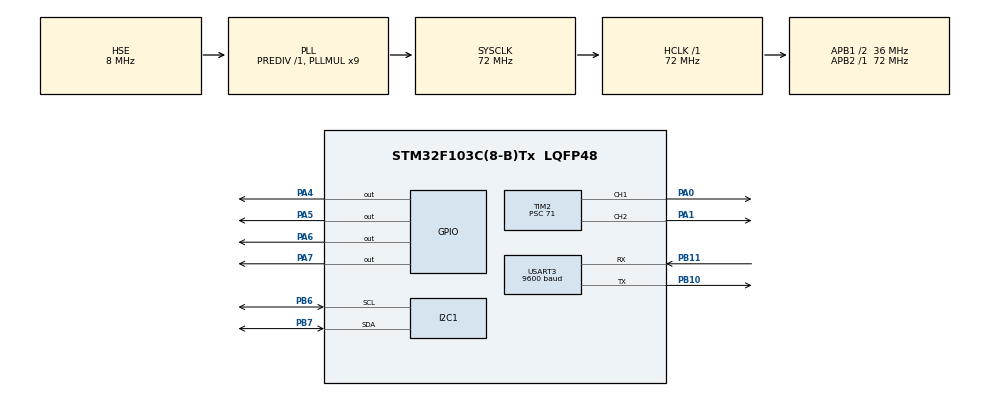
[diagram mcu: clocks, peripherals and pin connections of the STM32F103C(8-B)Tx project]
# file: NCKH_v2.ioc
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Mcu.Family=STM32F1
Mcu.Name=STM32F103C(8-B)Tx
Mcu.Package=LQFP48
NVIC.PriorityGroup=NVIC_PRIORITYGROUP_4
NVIC.TIM4_IRQn=true\:2\:0\:true\:false\:true\:true\:true
NVIC.USART3_IRQn=true\:0\:0\:true\:false\:true\:true\:true
PA0-WKUP.Signal=S_TIM2_CH1_ETR
PA1.Signal=S_TIM2_CH2
PA13.Mode=Serial_Wire
PA13.Signal=SYS_JTMS-SWDIO
PA14.Mode=Serial_Wire
PA14.Signal=SYS_JTCK-SWCLK
PA4.Signal=GPIO_Output
PA5.Signal=GPIO_Output
PA6.Signal=GPIO_Output
PA7.Signal=GPIO_Output
PB10.Mode=Asynchronous
PB10.Signal=USART3_TX
PB11.Mode=Asynchronous
PB11.Signal=USART3_RX
PB6.Mode=I2C
PB6.Signal=I2C1_SCL
PB7.Mode=I2C
PB7.Signal=I2C1_SDA
PD0-OSC_IN.Mode=HSE-External-Oscillator
PD0-OSC_IN.Signal=RCC_OSC_IN
PD1-OSC_OUT.Mode=HSE-External-Oscillator
PD1-OSC_OUT.Signal=RCC_OSC_OUT
ProjectManager.HeapSize=0x200
ProjectManager.StackSize=0x400
ProjectManager.TargetToolchain=MDK-ARM V5
RCC.AHBFreq_Value=72000000
RCC.APB1CLKDivider=RCC_HCLK_DIV2
RCC.APB1Freq_Value=36000000
RCC.APB1TimFreq_Value=72000000
RCC.APB2Freq_Value=72000000
RCC.APB2TimFreq_Value=72000000
RCC.HCLKFreq_Value=72000000
RCC.PLLMUL=RCC_PLL_MUL9
RCC.PLLSourceVirtual=RCC_PLLSOURCE_HSE
RCC.SYSCLKFreq_VALUE=72000000
RCC.SYSCLKSource=RCC_SYSCLKSOURCE_PLLCLK
RCC.USBFreq_Value=72000000
SH.S_TIM2_CH1_ETR.0=TIM2_CH1,PWM Generation1 CH1
SH.S_TIM2_CH2.0=TIM2_CH2,PWM Generation2 CH2
TIM2.Channel-PWM\ Generation1\ CH1=TIM_CHANNEL_1
TIM2.Channel-PWM\ Generation2\ CH2=TIM_CHANNEL_2
TIM2.Period=999
TIM2.Prescaler=71
TIM4.Period=9
TIM4.Prescaler=3600-1
USART3.BaudRate=9600
USART3.VirtualMode=VM_ASYNC
VP_TIM2_VS_ClockSourceINT.Mode=Internal
VP_TIM4_VS_ClockSourceINT.Mode=Internal
board=custom

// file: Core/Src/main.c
/* USER CODE BEGIN Header */
/**
  ******************************************************************************
  * @file           : main.c
  * @brief          : Main program body
  ******************************************************************************
  * @attention
  *
  * <h2><center>&copy; Copyright (c) 2022 STMicroelectronics.
  * All rights reserved.</center></h2>
  *
  * This software component is licensed by ST under BSD 3-Clause license,
  * the "License"; You may not use this file except in compliance with the
  * License. You may obtain a copy of the License at:
  *                        opensource.org/licenses/BSD-3-Clause
  *
  ******************************************************************************
  */
/* USER CODE END Header */
#include "main.h"
#include "stdlib.h"
#include "stdio.h"
#include "string.h"
#include "mpu6050.h"
#include "PID.h"
/* USER CODE BEGIN Includes */
float time_0 = 0.0;
float time_1 = 0.0;
float timeCurrent=0.0;
// -----------------pid----------------------------
#define TEST_MODE (0)
#define NORMAL_MODE (1)
#define TIMER  (1)
#define SP_VALUE 180.5
#define SP_UP			SP_VALUE+2
#define SP_DOWN			SP_VALUE-2
#define TURN_SPEED 200
#define TIME_SAMPLE 0.001

float  u=0;
float  yu=0;
float yuT=0;
float yuP=0;
float uT=0;
float uP=0;
float AddT=0;
float AddP=0;

// 200 30 1
float SP = SP_VALUE;
float Pitch=0;
float Kp=350 ;//5.5 175
float Ki=55;//1.5
float Kd =1;//2

float ySP=0;
float Yaw=0;
float yKp=10;//5.5 175
float yKi=0;//1.5
float yKd =0;//2

float Error_calib=0.1288;

float pTerm, iTerm, dTerm, last_error, error;
float ypTerm, yiTerm, ydTerm, ylast_error, yerror;

			const char s[5]=",-";
			char* str_Angle;
			char* str_Kp;
			char* str_Ki;
			char* str_Kd;
			char Tx_data[10]="OK";
char Rx_data;
int Rx_index;
char Rx_data1[100];
char Rx_data2[100];
int Rx_flag;

I2C_HandleTypeDef hi2c1;

TIM_HandleTypeDef htim2;
TIM_HandleTypeDef htim4;

UART_HandleTypeDef huart3;

void SystemClock_Config(void);
static void MX_GPIO_Init(void);
static void MX_TIM2_Init(void);
static void MX_TIM4_Init(void);
static void MX_I2C1_Init(void);
static void MX_USART3_UART_Init(void);
//-------------------------------------------function---------------------
#if TIMER
void HAL_TIM_PeriodElapsedCallback(TIM_HandleTypeDef *htim){
	if(htim->Instance==htim4.Instance){

//------------------------------------------------------UART----------------------------------------
#if NORMAL_MODE
			HAL_UART_Receive_IT(&huart3,(uint8_t*)&Rx_data,1);

			SP=SP_VALUE;
			AddT=0;
			AddP=0;
//			uP=0;
//			uT=0;

			if(Rx_data=='U'){
			SP=SP_UP;
			ySP=ySP;
//			AddT=0;
//			AddP=0;
		}else if(Rx_data=='D'){
			SP=SP_DOWN;
			ySP=ySP;
//			if(Yaw>0){
//				ySP=180;
//			}else ySP=-180;

//			AddT=0;
//			AddP=0;

		}else if(Rx_data=='R'){
			SP=SP_VALUE;
		//	ySP=90;
			ySP+=0.1;

//			AddT=-TURN_SPEED;
//			AddP=TURN_SPEED;
		}else if(Rx_data=='L'){
			SP=SP_VALUE;
			//ySP=-90;
			ySP-=0.1;
//			AddT=TURN_SPEED;
//			AddP=-TURN_SPEED;
		}else if(Rx_data=='u'){
			SP=SP_UP;
			ySP=ySP;
//			AddT=TURN_SPEED;
//			AddP=-TURN_SPEED;
		}else if(Rx_data=='d'){
			SP=SP_DOWN;
			ySP=ySP;
//			AddT=TURN_SPEED;
//			AddP=-TURN_SPEED;
		}else if(Rx_data=='O'){
			SP=SP_VALUE;
			ySP=ySP;
//			AddT=0;
//			AddP=0;
		}else{
			SP=SP_VALUE;
			ySP=ySP;
//			AddT=0;
//			AddP=0;
		}
#endif
//---------------------------------------------------PID---------------------------------------------------------
					MPU6050_GET_ANGLE(&hi2c1,&Pitch,&Yaw,Error_calib,TIME_SAMPLE);
					u = PID(SP,Pitch,Kp,Ki,Kd,&error,&last_error,&pTerm,&iTerm,&dTerm);
					yu= PID(ySP,Yaw,yKp,yKi,yKd,&yerror,&ylast_error,&ypTerm,&yiTerm,&ydTerm);

							yuT=yu;
							yuP=-yu;

//			if(yuT<0) // angle>180
//				{
//					yuT=0-yuT;
//					HAL_GPIO_WritePin(GPIOA,GPIO_PIN_4,GPIO_PIN_SET);//A1
//					HAL_GPIO_WritePin(GPIOA,GPIO_PIN_5,GPIO_PIN_RESET);//B1
//					__HAL_TIM_SetCompare(&htim2,TIM_CHANNEL_1,yuT);//98

//				}
//				else
//				{
//					HAL_GPIO_WritePin(GPIOA,GPIO_PIN_4,GPIO_PIN_RESET);//A1
//					HAL_GPIO_WritePin(GPIOA,GPIO_PIN_5,GPIO_PIN_SET);//B1
//					__HAL_TIM_SetCompare(&htim2,TIM_CHANNEL_1,yuT);
//
//				}
//			if(yuP<0) // angle>180
//				{
//					yuP=0-yuP;
//					HAL_GPIO_WritePin(GPIOA,GPIO_PIN_6,GPIO_PIN_SET);//A1
//					HAL_GPIO_WritePin(GPIOA,GPIO_PIN_7,GPIO_PIN_RESET);//B1
//					__HAL_TIM_SetCompare(&htim2,TIM_CHANNEL_2,yuP);//98

//				}
//				else
//				{
//					HAL_GPIO_WritePin(GPIOA,GPIO_PIN_6,GPIO_PIN_RESET);//A1
//					HAL_GPIO_WritePin(GPIOA,GPIO_PIN_7,GPIO_PIN_SET);//B1
//					__HAL_TIM_SetCompare(&htim2,TIM_CHANNEL_2,yuP);
//
//				}

					uT=u+yuT;
					uP=u+yuP;
					Constant(&uT,999,-999);
					Constant(&uP,999,-999);
//					if ( uT > 999 ) {
//						uT = 999;}
//					else if ( uT< -999 ) uT= -999 ;
//					if ( uP > 999 ) {
//						uP = 999;}
//					else if ( uP< -999 ) uP= -999 ;
			if(uT<0)
				{
					uT=0-uT;
					HAL_GPIO_WritePin(GPIOA,GPIO_PIN_4,GPIO_PIN_SET);//A1
					HAL_GPIO_WritePin(GPIOA,GPIO_PIN_5,GPIO_PIN_RESET);//B1
					__HAL_TIM_SetCompare(&htim2,TIM_CHANNEL_1,uT);//98

				}
				else
				{
					HAL_GPIO_WritePin(GPIOA,GPIO_PIN_4,GPIO_PIN_RESET);//A1
					HAL_GPIO_WritePin(GPIOA,GPIO_PIN_5,GPIO_PIN_SET);//B1
					__HAL_TIM_SetCompare(&htim2,TIM_CHANNEL_1,uT);

				}
			if(uP<0) // angle>180
				{
					uP=0-uP;
					HAL_GPIO_WritePin(GPIOA,GPIO_PIN_6,GPIO_PIN_SET);//A1
					HAL_GPIO_WritePin(GPIOA,GPIO_PIN_7,GPIO_PIN_RESET);//B1
					__HAL_TIM_SetCompare(&htim2,TIM_CHANNEL_2,uP);//98

				}
				else
				{
					HAL_GPIO_WritePin(GPIOA,GPIO_PIN_6,GPIO_PIN_RESET);//A1
					HAL_GPIO_WritePin(GPIOA,GPIO_PIN_7,GPIO_PIN_SET);//B1
					__HAL_TIM_SetCompare(&htim2,TIM_CHANNEL_2,uP);

				}

		}
}
#endif
void Split_String(){

			strcpy(Rx_data2,Rx_data1);
			str_Angle=strtok(Rx_data2,s);
			str_Kp=strtok(NULL,s);
			str_Ki=strtok(NULL,s);
			str_Kd=strtok(NULL,s);
			if(strcmp(str_Angle,"pitch")==0){
					Kp=strtof(str_Kp,NULL);
					Ki=strtof(str_Ki,NULL);
					Kd=strtof(str_Kd,NULL);
			}else if(strcmp(str_Angle,"yaw")==0){
					yKp=strtof(str_Kp,NULL);
					yKi=strtof(str_Ki,NULL);
					yKd=strtof(str_Kd,NULL);
			}

}
#if TEST_MODE
void HAL_UART_RxCpltCallback(UART_HandleTypeDef *huart){
	if(huart->Instance==USART3){

			if (Rx_index == 0)
				{
					for(int i=0;i<100;i++){
					Rx_data1[i]=NULL;
					//	Rx_data2[i]=0;
					}
				}
			if(Rx_data!='r'){
					Rx_data1[Rx_index++]=Rx_data;
			}else{
				//Rx_data1[Rx_index++]='\0';
				Split_String();
				Rx_index=0;
			}
		HAL_UART_Receive_IT(&huart3,(uint8_t*)&Rx_data,1);
	}
}
#endif
/* USER CODE END 0 */

int main(void)
{

  /* MCU Configuration--------------------------------------------------------*/

  /* Reset of all peripherals, Initializes the Flash interface and the Systick. */
  HAL_Init();

  /* Configure the system clock */
  SystemClock_Config();

  /* Initialize all configured peripherals */
  MX_GPIO_Init();
  MX_TIM2_Init();
  MX_TIM4_Init();
  MX_I2C1_Init();
  MX_USART3_UART_Init();
  /* USER CODE BEGIN 2 */
	MPU6050_Init(&hi2c1);
	HAL_UART_Receive_IT(&huart3,(uint8_t*)&Rx_data,1);
	//calib_MPU6050(&hi2c1,20000,&Error_calib);
		HAL_TIM_PWM_Start(&htim2, TIM_CHANNEL_1);
	HAL_TIM_PWM_Start(&htim2, TIM_CHANNEL_2);
		HAL_TIM_Base_Start_IT(&htim4);
	//HAL_UART_Receive_DMA(&huart3,(uint8_t*)&Rx_data,1);
  /* USER CODE END 2 */

  /* Infinite loop */
  while (1)
  {

  }
}

void SystemClock_Config(void)
{
  RCC_OscInitTypeDef RCC_OscInitStruct = {0};
  RCC_ClkInitTypeDef RCC_ClkInitStruct = {0};

  /** Initializes the RCC Oscillators according to the specified parameters
  * in the RCC_OscInitTypeDef structure.
  */
  RCC_OscInitStruct.OscillatorType = RCC_OSCILLATORTYPE_HSE;
  RCC_OscInitStruct.HSEState = RCC_HSE_ON;
  RCC_OscInitStruct.HSEPredivValue = RCC_HSE_PREDIV_DIV1;
  RCC_OscInitStruct.HSIState = RCC_HSI_ON;
  RCC_OscInitStruct.PLL.PLLState = RCC_PLL_ON;
  RCC_OscInitStruct.PLL.PLLSource = RCC_PLLSOURCE_HSE;
  RCC_OscInitStruct.PLL.PLLMUL = RCC_PLL_MUL9;
  if (HAL_RCC_OscConfig(&RCC_OscInitStruct) != HAL_OK)
  {
    Error_Handler();
  }
  /** Initializes the CPU, AHB and APB buses clocks
  */
  RCC_ClkInitStruct.ClockType = RCC_CLOCKTYPE_HCLK|RCC_CLOCKTYPE_SYSCLK
                              |RCC_CLOCKTYPE_PCLK1|RCC_CLOCKTYPE_PCLK2;
  RCC_ClkInitStruct.SYSCLKSource = RCC_SYSCLKSOURCE_PLLCLK;
  RCC_ClkInitStruct.AHBCLKDivider = RCC_SYSCLK_DIV1;
  RCC_ClkInitStruct.APB1CLKDivider = RCC_HCLK_DIV2;
  RCC_ClkInitStruct.APB2CLKDivider = RCC_HCLK_DIV1;

  if (HAL_RCC_ClockConfig(&RCC_ClkInitStruct, FLASH_LATENCY_2) != HAL_OK)
  {
    Error_Handler();
  }
}

static void MX_I2C1_Init(void)
{

  hi2c1.Instance = I2C1;
  hi2c1.Init.ClockSpeed = 100000;
  hi2c1.Init.DutyCycle = I2C_DUTYCYCLE_2;
  hi2c1.Init.OwnAddress1 = 0;
  hi2c1.Init.AddressingMode = I2C_ADDRESSINGMODE_7BIT;
  hi2c1.Init.DualAddressMode = I2C_DUALADDRESS_DISABLE;
  hi2c1.Init.OwnAddress2 = 0;
  hi2c1.Init.GeneralCallMode = I2C_GENERALCALL_DISABLE;
  hi2c1.Init.NoStretchMode = I2C_NOSTRETCH_DISABLE;
  if (HAL_I2C_Init(&hi2c1) != HAL_OK)
  {
    Error_Handler();
  }

}

static void MX_TIM2_Init(void)
{

  TIM_ClockConfigTypeDef sClockSourceConfig = {0};
  TIM_MasterConfigTypeDef sMasterConfig = {0};
  TIM_OC_InitTypeDef sConfigOC = {0};

  htim2.Instance = TIM2;
  htim2.Init.Prescaler = 71;
  htim2.Init.CounterMode = TIM_COUNTERMODE_UP;
  htim2.Init.Period = 999;
  htim2.Init.ClockDivision = TIM_CLOCKDIVISION_DIV1;
  htim2.Init.AutoReloadPreload = TIM_AUTORELOAD_PRELOAD_DISABLE;
  if (HAL_TIM_Base_Init(&htim2) != HAL_OK)
  {
    Error_Handler();
  }
  sClockSourceConfig.ClockSource = TIM_CLOCKSOURCE_INTERNAL;
  if (HAL_TIM_ConfigClockSource(&htim2, &sClockSourceConfig) != HAL_OK)
  {
    Error_Handler();
  }
  if (HAL_TIM_PWM_Init(&htim2) != HAL_OK)
  {
    Error_Handler();
  }
  sMasterConfig.MasterOutputTrigger = TIM_TRGO_RESET;
  sMasterConfig.MasterSlaveMode = TIM_MASTERSLAVEMODE_DISABLE;
  if (HAL_TIMEx_MasterConfigSynchronization(&htim2, &sMasterConfig) != HAL_OK)
  {
    Error_Handler();
  }
  sConfigOC.OCMode = TIM_OCMODE_PWM1;
  sConfigOC.Pulse = 0;
  sConfigOC.OCPolarity = TIM_OCPOLARITY_HIGH;
  sConfigOC.OCFastMode = TIM_OCFAST_DISABLE;
  if (HAL_TIM_PWM_ConfigChannel(&htim2, &sConfigOC, TIM_CHANNEL_1) != HAL_OK)
  {
    Error_Handler();
  }
  if (HAL_TIM_PWM_ConfigChannel(&htim2, &sConfigOC, TIM_CHANNEL_2) != HAL_OK)
  {
    Error_Handler();
  }
  HAL_TIM_MspPostInit(&htim2);

}

static void MX_TIM4_Init(void)
{

  TIM_ClockConfigTypeDef sClockSourceConfig = {0};
  TIM_MasterConfigTypeDef sMasterConfig = {0};

  htim4.Instance = TIM4;
  htim4.Init.Prescaler = 3600-1;
  htim4.Init.CounterMode = TIM_COUNTERMODE_UP;
  htim4.Init.Period = 9;
  htim4.Init.ClockDivision = TIM_CLOCKDIVISION_DIV1;
  htim4.Init.AutoReloadPreload = TIM_AUTORELOAD_PRELOAD_DISABLE;
  if (HAL_TIM_Base_Init(&htim4) != HAL_OK)
  {
    Error_Handler();
  }
  sClockSourceConfig.ClockSource = TIM_CLOCKSOURCE_INTERNAL;
  if (HAL_TIM_ConfigClockSource(&htim4, &sClockSourceConfig) != HAL_OK)
  {
    Error_Handler();
  }
  sMasterConfig.MasterOutputTrigger = TIM_TRGO_RESET;
  sMasterConfig.MasterSlaveMode = TIM_MASTERSLAVEMODE_DISABLE;
  if (HAL_TIMEx_MasterConfigSynchronization(&htim4, &sMasterConfig) != HAL_OK)
  {
    Error_Handler();
  }

}

static void MX_USART3_UART_Init(void)
{

  huart3.Instance = USART3;
  huart3.Init.BaudRate = 9600;
  huart3.Init.WordLength = UART_WORDLENGTH_8B;
  huart3.Init.StopBits = UART_STOPBITS_1;
  huart3.Init.Parity = UART_PARITY_NONE;
  huart3.Init.Mode = UART_MODE_TX_RX;
  huart3.Init.HwFlowCtl = UART_HWCONTROL_NONE;
  huart3.Init.OverSampling = UART_OVERSAMPLING_16;
  if (HAL_UART_Init(&huart3) != HAL_OK)
  {
    Error_Handler();
  }

}

static void MX_GPIO_Init(void)
{
  GPIO_InitTypeDef GPIO_InitStruct = {0};

  /* GPIO Ports Clock Enable */
  __HAL_RCC_GPIOD_CLK_ENABLE();
  __HAL_RCC_GPIOA_CLK_ENABLE();
  __HAL_RCC_GPIOB_CLK_ENABLE();

  /*Configure GPIO pin Output Level */
  HAL_GPIO_WritePin(GPIOA, GPIO_PIN_4|GPIO_PIN_5|GPIO_PIN_6|GPIO_PIN_7, GPIO_PIN_RESET);

  /*Configure GPIO pins : PA4 PA5 PA6 PA7 */
  GPIO_InitStruct.Pin = GPIO_PIN_4|GPIO_PIN_5|GPIO_PIN_6|GPIO_PIN_7;
  GPIO_InitStruct.Mode = GPIO_MODE_OUTPUT_PP;
  GPIO_InitStruct.Pull = GPIO_NOPULL;
  GPIO_InitStruct.Speed = GPIO_SPEED_FREQ_LOW;
  HAL_GPIO_Init(GPIOA, &GPIO_InitStruct);

}

void Error_Handler(void)
{
  __disable_irq();
  while (1)
  {
  }
}

/************************ (C) COPYRIGHT STMicroelectronics *****END OF FILE****/
